# LargeDummyDevice register map
File version: 1.0
Registers are 32-bit, read-write, no defined reset value unless marked. A register's access mark holds for its fields unless they carry their own. Offsets are from the block's base; [hi:lo] are bit positions.

## PERIPHERAL_21
Base 0x40014000
0x04 REG_1 — Register 1
  [32:30] FIELD_2, [16] FIELD_1, [18:16] FIELD_3, [18:16] FIELD_4, [15:11] FIELD_5
0x08 REG_2 — Register 2
  [31:29] FIELD_8, [33:29] FIELD_18, [27:26] FIELD_10, [28:25] FIELD_1, [25:22] FIELD_9, [24:22] FIELD_19, [22:21] FIELD_2, [21] FIELD_22, [15] FIELD_4, [19:15] FIELD_16, [17:15] FIELD_17, [17:15] FIELD_23, [17:14] FIELD_21, [14:12] FIELD_11, [14:10] FIELD_3, [13:9] FIELD_5, [13:9] FIELD_14, [12:9] FIELD_20, [6] FIELD_12, [8:4] FIELD_15, [5:2] FIELD_7, [4:2] FIELD_13, [2:0] FIELD_6
0x0C REG_3 — Register 3
  [28:26] FIELD_4, [25:24] FIELD_7, [26:23] FIELD_5, [14:13] FIELD_9, [15:11] FIELD_1, [11:7] FIELD_3, [2:1] FIELD_6, [3:1] FIELD_8, [3:0] FIELD_2
0x10 REG_4 — Register 4
  [26:23] FIELD_1, [11:10] FIELD_4, [12:9] FIELD_3, [5] FIELD_2
0x14 REG_5 — Register 5
  [23:21] FIELD_2, [21:20] FIELD_4, [21:17] FIELD_5, [19:16] FIELD_3, [17:15] FIELD_1, [10:7] FIELD_6
0x18 REG_6 — Register 6
  [29] FIELD_9, [32:28] FIELD_3, [21:18] FIELD_7, [22:18] FIELD_8, [20:17] FIELD_2, [20:16] FIELD_5, [11] FIELD_10, [3] FIELD_6, [3:2] FIELD_4, [3:0] FIELD_1
0x1C REG_7 — Register 7
  [26:25] FIELD_1, [26:24] FIELD_2
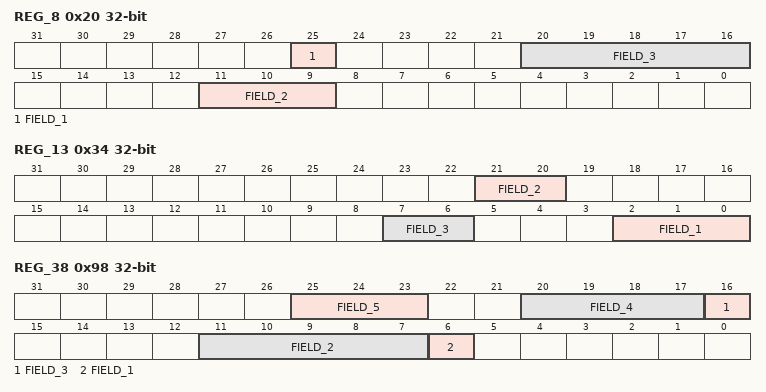
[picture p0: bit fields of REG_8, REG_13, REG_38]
0x20 REG_8 — Register 8
  [25] FIELD_1, [20:16] FIELD_3, [11:9] FIELD_2
0x24 REG_9 — Register 9
  [31:29] FIELD_11, [29:28] FIELD_8, [30:28] FIELD_10, [26] FIELD_4, [25] FIELD_3, [29:25] FIELD_5, [28:25] FIELD_7, [26:25] FIELD_18, [27:23] FIELD_20, [22] FIELD_19, [21] FIELD_9, [25:21] FIELD_12, [20] FIELD_2, [21:20] FIELD_17, [19] FIELD_13, [19] FIELD_21, [19] FIELD_22, [13] FIELD_15, [13:11] FIELD_14, [10:9] FIELD_16, [11:9] FIELD_27, [11:7] FIELD_26, [8:4] FIELD_1, [8:4] FIELD_6, [2] FIELD_25, [0] FIELD_23, [2:0] FIELD_24
0x28 REG_10 — Register 10
  [16:15] FIELD_1
0x2C REG_11 — Register 11
  [33:31] FIELD_1
0x30 REG_12 — Register 12
  [30] FIELD_1, [30:26] FIELD_2, [17:16] FIELD_8, [14:13] FIELD_5, [15:11] FIELD_7, [13:9] FIELD_4, [8] FIELD_3, [7:3] FIELD_6
0x34 REG_13 — Register 13
  [21:20] FIELD_2, [7:6] FIELD_3, [2:0] FIELD_1
0x38 REG_14 — Register 14
  [31] FIELD_12, [30] FIELD_14, [27] FIELD_2, [30:27] FIELD_3, [29:26] FIELD_20, [22] FIELD_16, [22] FIELD_18, [23:21] FIELD_1, [25:21] FIELD_6, [21:20] FIELD_5, [19:18] FIELD_4, [18:17] FIELD_7, [16:14] FIELD_11, [13:11] FIELD_19, [9:8] FIELD_17, [8:7] FIELD_13, [5] FIELD_8, [5] FIELD_9, [6:3] FIELD_15, [1:0] FIELD_10
0x3C REG_15 — Register 15
  [29:25] FIELD_5, [25:24] FIELD_2, [24:22] FIELD_4, [20:19] FIELD_1, [11] FIELD_3
0x40 REG_16 — Register 16
  [33:31] FIELD_7, [30:29] FIELD_6, [28:27] FIELD_10, [22:20] FIELD_2, [20:19] FIELD_11, [16:14] FIELD_9, [13] FIELD_5, [15:12] FIELD_12, [8] FIELD_4, [11:8] FIELD_8, [10:6] FIELD_1, [4:3] FIELD_3
0x44 REG_17 — Register 17
  [31] FIELD_6, [34:30] FIELD_4, [33:29] FIELD_15, [33:29] FIELD_20, [32:29] FIELD_21, [28:27] FIELD_1, [21] FIELD_14, [22:20] FIELD_22, [21:19] FIELD_3, [19] FIELD_19, [20:18] FIELD_16, [19:16] FIELD_12, [20:16] FIELD_17, [15:14] FIELD_11, [16:12] FIELD_10, [13:11] FIELD_7, [9] FIELD_5, [11:8] FIELD_18, [9:6] FIELD_8, [8:5] FIELD_2, [4:1] FIELD_9, [2:1] FIELD_13
0x48 REG_18 — Register 18
  [34:30] FIELD_1, [25] FIELD_13, [26:23] FIELD_10, [23:22] FIELD_11, [21:20] FIELD_7, [20:17] FIELD_3, [21:17] FIELD_6, [13:10] FIELD_9, [8:7] FIELD_8, [9:6] FIELD_4, [7:4] FIELD_2, [4:3] FIELD_5, [4:0] FIELD_12
0x4C REG_19 — Register 19
  [35:31] FIELD_22, [33:29] FIELD_8, [29:27] FIELD_25, [25] FIELD_3, [28:25] FIELD_10, [27:24] FIELD_11, [24] FIELD_26, [23:21] FIELD_14, [24:21] FIELD_28, [22:20] FIELD_13, [20] FIELD_18, [24:20] FIELD_21, [22:19] FIELD_15, [23:19] FIELD_16, [18:17] FIELD_6, [21:17] FIELD_19, [19:17] FIELD_27, [17:14] FIELD_2, [17:13] FIELD_24, [17:13] FIELD_30, [15:12] FIELD_29, [10] FIELD_20, [9:7] FIELD_9, [9:5] FIELD_7, [8:5] FIELD_12, [7:5] FIELD_32, [8:4] FIELD_31, [2:1] FIELD_1, [3:1] FIELD_4, [4:1] FIELD_5, [2:0] FIELD_17, [1:0] FIELD_23
0x50 REG_20 — Register 20
  [35:31] FIELD_13, [31] FIELD_20, [32:29] FIELD_7, [27] FIELD_12, [30:27] FIELD_24, [25] FIELD_1, [24:23] FIELD_4, [23] FIELD_22, [25:22] FIELD_23, [21] FIELD_6, [21:20] FIELD_8, [19:18] FIELD_25, [18] FIELD_27, [20:17] FIELD_3, [19:17] FIELD_11, [18:15] FIELD_5, [17:15] FIELD_16, [12:10] FIELD_26, [9] FIELD_15, [13:9] FIELD_21, [10:7] FIELD_9, [6] FIELD_18, [5:4] FIELD_2, [7:3] FIELD_14, [5:3] FIELD_17, [5:3] FIELD_19, [6:3] FIELD_29, [3:2] FIELD_28, [5:1] FIELD_10
0x54 REG_21 — Register 21
  [33:31] FIELD_7, [33:29] FIELD_10, [25] FIELD_11, [25:24] FIELD_13, [24:23] FIELD_9, [25:23] FIELD_15, [23:20] FIELD_3, [19:18] FIELD_20, [16] FIELD_2, [14:13] FIELD_8, [17:13] FIELD_17, [14:11] FIELD_1, [15:11] FIELD_5, [11] FIELD_12, [14:10] FIELD_16, [9:8] FIELD_19, [12:8] FIELD_21, [8:6] FIELD_14, [2:1] FIELD_4, [2:0] FIELD_6, [1:0] FIELD_18
0x58 REG_22 — Register 22
  [32:31] FIELD_9, [32:28] FIELD_18, [26:22] FIELD_19, [24:22] FIELD_24, [22:18] FIELD_7, [17] FIELD_8, [18:16] FIELD_12, [16] FIELD_20, [16:15] FIELD_22, [16:13] FIELD_17, [12] FIELD_5, [13:10] FIELD_2, [13:9] FIELD_3, [11:7] FIELD_4, [8:6] FIELD_11, [9:6] FIELD_16, [6:4] FIELD_1, [4:3] FIELD_6, [7:3] FIELD_13, [5:3] FIELD_23, [5:2] FIELD_14, [6:2] FIELD_15, [5:1] FIELD_10, [0] FIELD_21
0x5C REG_23 — Register 23
  [33:29] FIELD_8, [14:13] FIELD_3, [13:9] FIELD_6, [8:7] FIELD_4, [6] FIELD_5, [5:4] FIELD_7, [5:2] FIELD_1, [3:1] FIELD_2
0x60 REG_24 — Register 24
  [30] FIELD_1, [28] FIELD_12, [29:27] FIELD_3, [30:27] FIELD_17, [28:24] FIELD_7, [28:24] FIELD_16, [27:23] FIELD_11, [20] FIELD_9, [22:20] FIELD_10, [21:19] FIELD_4, [16:14] FIELD_8, [15:14] FIELD_18, [9:7] FIELD_5, [10:7] FIELD_13, [2:1] FIELD_2, [5:1] FIELD_15, [0] FIELD_6, [0] FIELD_14
0x64 REG_25 — Register 25
  [13:11] FIELD_1, [7:4] FIELD_2, [4:2] FIELD_3, [3:0] FIELD_4
0x68 REG_26 — Register 26
  [34:31] FIELD_1, [31:29] FIELD_16, [31:28] FIELD_10, [30:26] FIELD_18, [28:26] FIELD_21, [28:25] FIELD_3, [25] FIELD_5, [26:25] FIELD_13, [22] FIELD_7, [25:21] FIELD_24, [20:19] FIELD_4, [22:19] FIELD_15, [20:18] FIELD_14, [18:16] FIELD_8, [17:15] FIELD_20, [15:14] FIELD_11, [15:14] FIELD_19, [15:12] FIELD_9, [12] FIELD_22, [10] FIELD_6, [13:9] FIELD_12, [11:8] FIELD_17, [5:3] FIELD_2, [5:2] FIELD_23
0x6C REG_27 — Register 27
  [33:29] FIELD_2, [30:29] FIELD_10, [28] FIELD_8, [28:27] FIELD_6, [25] FIELD_11, [28:24] FIELD_3, [28:24] FIELD_7, [17:15] FIELD_13, [15:13] FIELD_12, [12:10] FIELD_4, [12:9] FIELD_14, [7] FIELD_5, [11:7] FIELD_9, [5:1] FIELD_1
0x70 REG_28 — Register 28
  [29] FIELD_9, [31:28] FIELD_4, [30:26] FIELD_7, [22] FIELD_5, [20:18] FIELD_8, [17:15] FIELD_1, [8:6] FIELD_2, [6:3] FIELD_6, [6:2] FIELD_3
0x74 REG_29 — Register 29
  [32:31] FIELD_4, [30] FIELD_6, [34:30] FIELD_20, [28] FIELD_10, [32:28] FIELD_11, [28:27] FIELD_1, [30:26] FIELD_2, [30:26] FIELD_8, [26] FIELD_9, [28:26] FIELD_15, [28:25] FIELD_17, [26:25] FIELD_24, [21:20] FIELD_21, [18:16] FIELD_7, [12:11] FIELD_16, [12:8] FIELD_5, [8:7] FIELD_3, [9:7] FIELD_22, [11:7] FIELD_23, [9:6] FIELD_13, [5:4] FIELD_12, [7:3] FIELD_19, [3:1] FIELD_14, [0] FIELD_18
0x78 REG_30 — Register 30
  [26] FIELD_3, [16] FIELD_1, [15:14] FIELD_2, [15:13] FIELD_7, [11:8] FIELD_6, [5] FIELD_4, [5] FIELD_8, [4] FIELD_5
0x7C REG_31 — Register 31
  [31] FIELD_3, [29:26] FIELD_7, [30:26] FIELD_13, [22:21] FIELD_17, [24:20] FIELD_9, [24:20] FIELD_11, [18:17] FIELD_22, [15] FIELD_5, [16:14] FIELD_19, [16:14] FIELD_26, [14:13] FIELD_4, [13] FIELD_8, [13:11] FIELD_14, [10:8] FIELD_24, [8:7] FIELD_12, [7] FIELD_15, [10:7] FIELD_20, [8:6] FIELD_1, [6] FIELD_10, [8:6] FIELD_18, [7:5] FIELD_2, [9:5] FIELD_21, [7:5] FIELD_25, [2] FIELD_16, [1] FIELD_23, [2:0] FIELD_6
0x80 REG_32 — Register 32
  [31] FIELD_1, [33:31] FIELD_17, [31:29] FIELD_4, [29:28] FIELD_10, [30:28] FIELD_16, [28:25] FIELD_3, [25] FIELD_14, [27:25] FIELD_19, [24:21] FIELD_6, [21:20] FIELD_12, [19] FIELD_20, [21:19] FIELD_21, [22:18] FIELD_5, [19:16] FIELD_9, [8:7] FIELD_8, [7:5] FIELD_13, [8:4] FIELD_7, [6:4] FIELD_15, [7:3] FIELD_11, [4:2] FIELD_2, [3:1] FIELD_18
0x84 REG_33 — Register 33
  [35:31] FIELD_5, [31:30] FIELD_7, [30:29] FIELD_6, [24] FIELD_2, [26:24] FIELD_18, [26:23] FIELD_3, [27:23] FIELD_4, [25:23] FIELD_15, [21] FIELD_1, [23:21] FIELD_20, [21:20] FIELD_8, [24:20] FIELD_11, [21:17] FIELD_9, [14] FIELD_12, [15:14] FIELD_16, [11] FIELD_13, [12:10] FIELD_14, [10] FIELD_19, [10:6] FIELD_17, [7:3] FIELD_10
0x88 REG_34 — Register 34
  [33:31] FIELD_9, [30] FIELD_3, [33:30] FIELD_20, [31:28] FIELD_15, [26] FIELD_18, [27:26] FIELD_19, [28:25] FIELD_8, [27:25] FIELD_14, [26:24] FIELD_21, [25:23] FIELD_10, [19] FIELD_5, [21:17] FIELD_7, [15] FIELD_13, [13] FIELD_11, [15:12] FIELD_1, [15:12] FIELD_6, [14:12] FIELD_16, [13:12] FIELD_17, [5] FIELD_2, [3:0] FIELD_4, [0] FIELD_12, [1:0] FIELD_22
0x8C REG_35 — Register 35
  [31:29] FIELD_5, [32:28] FIELD_4, [25:24] FIELD_3, [24:22] FIELD_19, [23:21] FIELD_7, [21] FIELD_11, [24:20] FIELD_1, [21:20] FIELD_12, [20:17] FIELD_10, [19:17] FIELD_15, [14] FIELD_18, [13:11] FIELD_17, [8] FIELD_8, [8:6] FIELD_9, [8:5] FIELD_16, [4:3] FIELD_2, [4:2] FIELD_13, [3:1] FIELD_6, [3:0] FIELD_14
0x90 REG_36 — Register 36
  [35:31] FIELD_18, [30] FIELD_10, [32:29] FIELD_11, [28:25] FIELD_1, [28:25] FIELD_14, [20] FIELD_8, [24:20] FIELD_13, [21:17] FIELD_12, [19:17] FIELD_21, [15] FIELD_7, [16:15] FIELD_20, [15:12] FIELD_16, [15:11] FIELD_22, [12:9] FIELD_3, [12:9] FIELD_6, [11:8] FIELD_2, [7] FIELD_17, [7:5] FIELD_5, [8:4] FIELD_23, [5:3] FIELD_9, [4:3] FIELD_15, [5:2] FIELD_19, [5:1] FIELD_4
0x94 REG_37 — Register 37
  [33:30] FIELD_5, [28:26] FIELD_3, [23] FIELD_1, [19:18] FIELD_2, [19:17] FIELD_4, [12] FIELD_8, [13:11] FIELD_6, [9:8] FIELD_7
0x98 REG_38 — Register 38
  [25:23] FIELD_5, [20:17] FIELD_4, [16] FIELD_3, [11:7] FIELD_2, [6] FIELD_1
0x9C REG_39 — Register 39
  [32:31] FIELD_17, [28:27] FIELD_18, [26] FIELD_23, [29:25] FIELD_3, [26:25] FIELD_10, [25:23] FIELD_1, [24:23] FIELD_9, [24:23] FIELD_29, [17] FIELD_8, [17:15] FIELD_24, [14] FIELD_22, [16:13] FIELD_15, [17:13] FIELD_21, [12] FIELD_2, [15:11] FIELD_7, [9:8] FIELD_5, [9:8] FIELD_16, [10:7] FIELD_11, [8:6] FIELD_26, [9:5] FIELD_6, [7:4] FIELD_12, [4] FIELD_27, [7:3] FIELD_28, [6:2] FIELD_4, [5:2] FIELD_25, [4:1] FIELD_13, [3:1] FIELD_14, [3:1] FIELD_19, [5:1] FIELD_20, [4:0] FIELD_30
0xA0 REG_40 — Register 40
  [31] FIELD_4, [31:30] FIELD_1, [33:29] FIELD_7, [29] FIELD_11, [30:28] FIELD_2, [29:26] FIELD_12, [23:21] FIELD_10, [21:20] FIELD_8, [22:19] FIELD_9, [12] FIELD_6, [12:11] FIELD_5, [11:9] FIELD_3
